# STM32H7B3 register map
File version: 3.3
CPU: CM7 r0p1, little endian, MPU, FPU, 4 interrupt priority bits
Registers are 32-bit, read-write, reset 0x0 unless marked. A register's access mark holds for its fields unless they carry their own. Offsets are from the block's base; [hi:lo] are bit positions; {n}, {i} and the like mark numbered series.

## BDMA1 — Basic direct memory access controller
Base 0x48022C00
Same registers: BDMA2 0x58025400
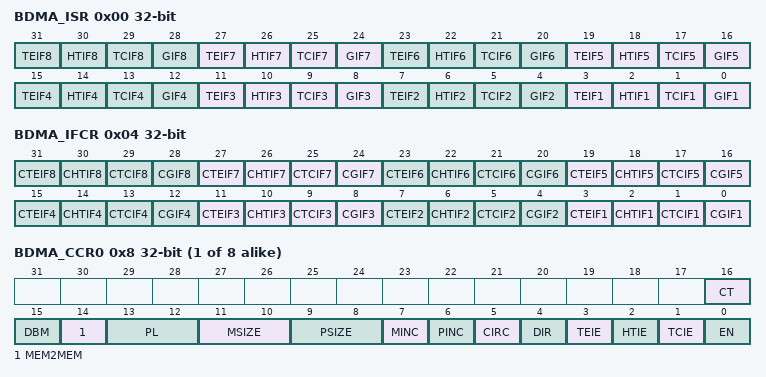
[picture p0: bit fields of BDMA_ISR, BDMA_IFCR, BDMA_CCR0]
0x00 BDMA_ISR ro — DMA interrupt status register
  [4n-1] TEIF{n} (n=1..8) — Channel x transfer error flag (x = 1..8) This bit is set by hardware. It is cleared by software writing 1 to the corresponding bit in the DMA_IFCR register.
  [4n-2] HTIF{n} (n=1..8) — Channel x half transfer flag (x = 1..8) This bit is set by hardware. It is cleared by software writing 1 to the corresponding bit in the DMA_IFCR register.
  [4n-3] TCIF{n} (n=1..8) — Channel x transfer complete flag (x = 1..8) This bit is set by hardware. It is cleared by software writing 1 to the corresponding bit in the DMA_IFCR register.
  [4n-4] GIF{n} (n=1..8) — Channel x global interrupt flag (x = 1..8) This bit is set by hardware. It is cleared by software writing 1 to the corresponding bit in the DMA_IFCR register.
0x04 BDMA_IFCR wo — DMA interrupt flag clear register
  [4n-1] CTEIF{n} (n=1..8) — Channel x transfer error clear This bit is set and cleared by software.
  [4n-2] CHTIF{n} (n=1..8) — Channel x half transfer clear This bit is set and cleared by software.
  [4n-3] CTCIF{n} (n=1..8) — Channel x transfer complete clear This bit is set and cleared by software.
  [4n-4] CGIF{n} (n=1..8) — Channel x global interrupt clear This bit is set and cleared by software.
{0x8+0x14*i} BDMA_CCR{i} (i=0..7) — DMA channel x configuration register
  [16] CT — current target memory of DMA transfer in double-buffer mode.
  [15] DBM — double-buffer mode
  [14] MEM2MEM — Memory to memory mode This bit is set and cleared by software.
  [13:12] PL — Channel priority level These bits are set and cleared by software.
  [11:10] MSIZE — Memory size These bits are set and cleared by software.
  [9:8] PSIZE — Peripheral size These bits are set and cleared by software.
  [7] MINC — Memory increment mode This bit is set and cleared by software.
  [6] PINC — Peripheral increment mode This bit is set and cleared by software.
  [5] CIRC — Circular mode This bit is set and cleared by software.
  [4] DIR — Data transfer direction This bit is set and cleared by software.
  [3] TEIE — Transfer error interrupt enable This bit is set and cleared by software.
  [2] HTIE — Half transfer interrupt enable This bit is set and cleared by software.
  [1] TCIE — Transfer complete interrupt enable This bit is set and cleared by software.
  [0] EN — Channel enable This bit is set and cleared by software.
{0xC+0x14*i} BDMA_CNDTR{i} (i=0..7) — DMA channel x number of data register
  [15:0] NDT — Number of data to transfer Number of data to be transferred (0 up to 65535). This register can only be written when the channel is disabled. Once the channel is enabled, this register is read-only, indicating the remaining bytes to be transmitted. This register decrements after each DMA transfer. Once the transfer is completed, this register can either stay at zero or be reloaded automatically by the value previously programmed if the channel is configured in auto-reload mode. If this register is zero, no transaction can be served whether the channel is enabled or not.
{0x10+0x14*i} BDMA_CPAR{i} (i=0..7) — This register must not be written when the channel is enabled.
  [31:0] PA — Peripheral address Base address of the peripheral data register from/to which the data will be read/written. When PSIZE is 01 (16-bit), the PA[0] bit is ignored. Access is automatically aligned to a half-word address. When PSIZE is 10 (32-bit), PA[1:0] are ignored. Access is automatically aligned to a word address.
{0x14+0x14*i} BDMA_CM0AR{i} (i=0..7) — This register must not be written when the channel is enabled.
  [31:0] MA — Memory address Base address of the memory area from/to which the data will be read/written. When MSIZE is 01 (16-bit), the MA[0] bit is ignored. Access is automatically aligned to a half-word address. When MSIZE is 10 (32-bit), MA[1:0] are ignored. Access is automatically aligned to a word address.
0x18 BDMA_CM1AR0 — This register must not be written when the channel is enabled
0x2C BDMA_CM1AR1 — BDMA_CMAR1
0x40 BDMA_CM1AR2
0x54 BDMA_CM1AR3 — BDMA_CMAR3
0x68 BDMA_CM1AR4
{0x18+0x14*i} BDMA_CM1AR{i} (i=5..7) — This register must not be written when the channel is enabled.

## Notices in the file
Copyright (c) 2025 STMicroelectronics.
SPDX-License-Identifier: Apache-2.0
Licensed under the Apache License, Version 2.0 (the "License");
you may not use this file except in compliance with the License.
You may obtain a copy of the License at
http://www.apache.org/licenses/LICENSE-2.0
Unless required by applicable law or agreed to in writing, software
distributed under the License is distributed on an "AS IS" BASIS,
WITHOUT WARRANTIES OR CONDITIONS OF ANY KIND, either express or implied.
See the License for the specific language governing permissions and
limitations under the License.
